# S6E1A1 register map
File version: 1.1
Registers are 8-bit, read-write, reset 0x0 unless marked. A register's access mark holds for its fields unless they carry their own. Offsets are from the block's base; [hi:lo] are bit positions; {n}, {i} and the like mark numbered series.

## RTC — REAL-TIME CLOCK
Base 0x4003B000
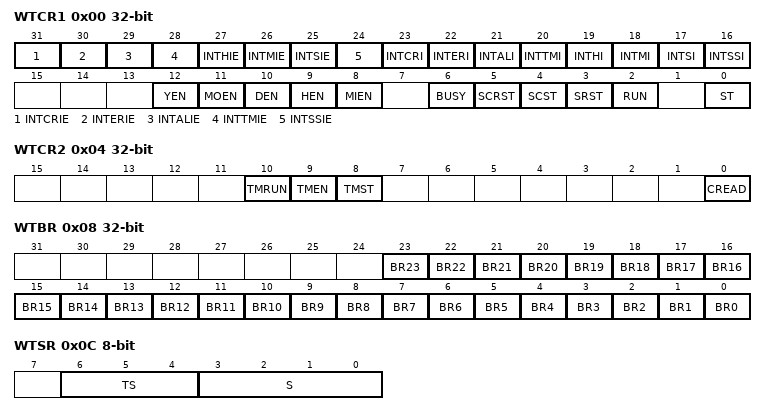
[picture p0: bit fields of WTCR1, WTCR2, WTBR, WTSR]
0x00 WTCR1 32-bit — Control Register 1
  [31] INTCRIE — Year/month/date/hour/minute/second/day of the week counter value read completion interrupt enable bit
  [30] INTERIE — Time rewrite error interrupt enable bit
  [29] INTALIE — Alarm interrupt enable bit
  [28] INTTMIE — Timer interrupt enable bit
  [27] INTHIE — 1-hour interrupt enable bit
  [26] INTMIE — 1-minute interrupt enable bit
  [25] INTSIE — 1-second interrupt enable bit
  [24] INTSSIE — 0.5-second interrupt enable bit
  [23] INTCRI — Year/month/date/hour/minute/second/day of the week counter value read completion interrupt flag bit
  [22] INTERI — Time rewrite error interrupt flag bit
  [21] INTALI — Alarm interrupt flag bit
  [20] INTTMI — Timer underflow flag bit
  [19] INTHI — 1-hour flag bit
  [18] INTMI — 1-minute flag bit
  [17] INTSI — 1-second flag bit
  [16] INTSSI — 0.5-second flag bit
  [12] YEN — Alarm year register enable bit
  [11] MOEN — Alarm month register enable bit
  [10] DEN — Alarm date register enable bit
  [9] HEN — Alarm hour register enable bit
  [8] MIEN — Alarm minute register enable bit
  [6] BUSY ro — Busy bit
  [5] SCRST — Sub second generation/1-second generation counter reset bit
  [4] SCST — 1-second clock output stop bit
  [3] SRST — RTC reset bit
  [2] RUN ro — RTC count block operation bit
  [0] ST — Start bit
0x04 WTCR2 32-bit — Control Register 2
  [10] TMRUN ro — Timer counter operation bit
  [9] TMEN — Timer counter control bit
  [8] TMST — Timer counter start bit
  [0] CREAD — Year/month/date/hour/minute/second/day of the week counter value read control bit
0x08 WTBR 32-bit — Counter Cycle Setting Register
  [n] BR{n} (n=0..23) — Bit{n} of WTBR
0x0C WTSR — Second Register
  [6:4] TS — The second digit of the second
  [3:0] S — The first digit of the second
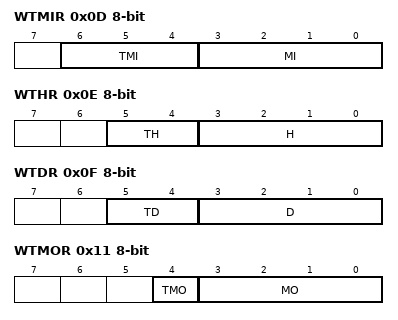
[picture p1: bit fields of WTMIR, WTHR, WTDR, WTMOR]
0x0D WTMIR — Minute Register
  [6:4] TMI — The second digit of the minute
  [3:0] MI — The first digit of the minute
0x0E WTHR — Hour register
  [5:4] TH — The second digit of the hour
  [3:0] H — The first digit of the hour
0x0F WTDR — Date Register
  [5:4] TD — The second digit of the date
  [3:0] D — The first digit of the date
0x10 WTDW — Day of the Week Register
  [2:0] DW — Day of the week
0x11 WTMOR — Month Register
  [4] TMO — The second digit in the month
  [3:0] MO — The first digit of the month
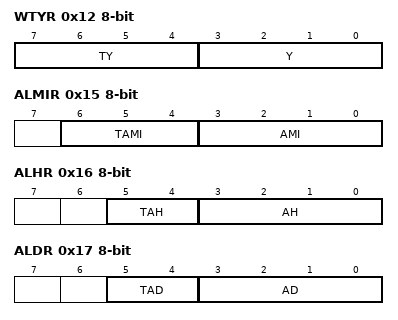
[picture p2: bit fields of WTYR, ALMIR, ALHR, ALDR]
0x12 WTYR — Year Register
  [7:4] TY — The second digit of the year
  [3:0] Y — The first digit of the year
0x15 ALMIR — Alarm Minute Register
  [6:4] TAMI — The second digit of the alarm-set minute
  [3:0] AMI — The first digit of the alarm-set minute
0x16 ALHR — Alarm Hour Register
  [5:4] TAH — The second digit of the alarm-set hour
  [3:0] AH — The first digit of the alarm-set hour
0x17 ALDR — Alarm Date Register
  [5:4] TAD — The second digit of the alarm-set date
  [3:0] AD — The first digit of the alarm-set date
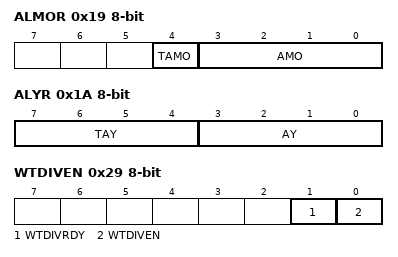
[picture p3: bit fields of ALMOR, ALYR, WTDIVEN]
0x19 ALMOR — Alarm Month Register
  [4] TAMO — The second digit of the alarm-set month
  [3:0] AMO — The first digit of the alarm-set month
0x1A ALYR — Alarm Years Register
  [7:4] TAY — The second digit of the alarm-set year
  [3:0] AY — The first digit of the alarm-set year
0x1C WTTR 32-bit — Timer Setting Register
  [17:0] TM — Timer setting register
0x20 WTCLKS — Clock Selection Register
  [0] WTCLKS — Input clock selection bit
0x21 WTCLKM ro — Selection Clock Status Register
  [1:0] WTCLKM — Clock selection status bits
0x24 WTCAL 16-bit — Frequency Correction Value Setting Register
  [9:0] WTCAL — Frequency correction value setting bits
0x26 WTCALEN — Frequency Correction Enable Register
  [0] WTCALEN — Frequency correction enable bit
0x28 WTDIV — Divider Ratio Setting Register
  [3:0] WTDIV — Divider ratio setting bits
0x29 WTDIVEN — Divider Output Enable Register
  [1] WTDIVRDY ro — Divider status bit
  [0] WTDIVEN — Divider enable bit
0x2C WTCALPRD reset 0x13 — Frenquency Correction Cycle Setting Register
  [5:0] WTCALPRD — Frenquency correction value setting bits
0x30 WTCOSEL — RTCCO Output Selection Register
  [0] WTCOSEL — RTCCO output selection bit
